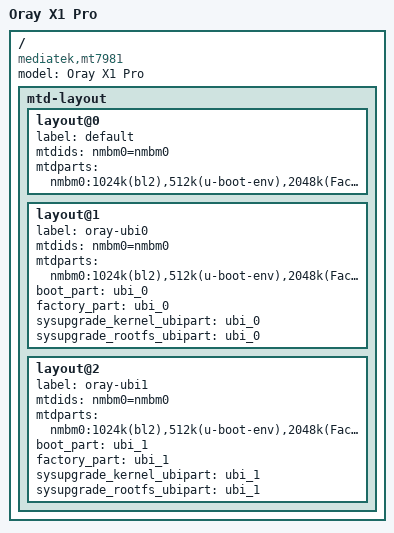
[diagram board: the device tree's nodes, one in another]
// SPDX-License-Identifier: GPL-2.0-or-later OR MIT

#include "mt7981-cudy-tr3000-v1.dts"

/ {
    compatible = "mediatek,mt7981", "mediatek,mt7981-rfb";
    model = "Oray X1 Pro";

	mtd-layout {
		layout@0 {
			label = "default";
			// mtd layout for immortalwrt/openwrt 112M ubi firmware
			mtdids = "nmbm0=nmbm0";
			mtdparts = "nmbm0:1024k(bl2),512k(u-boot-env),2048k(Factory),2048k(fip),512k(bdinfo),2048k(kpanic),114688k(ubi)";
		};

		layout@1 {
			label = "oray-ubi0";
			mtdids = "nmbm0=nmbm0";
			mtdparts = "nmbm0:1024k(bl2),512k(u-boot-env),2048k(Factory),2048k(fip),512k(bdinfo),2048k(kpanic),57344k(ubi_0),57344k(ubi_1)";
			boot_part = "ubi_0";
			factory_part = "ubi_0";
			sysupgrade_kernel_ubipart = "ubi_0";
			sysupgrade_rootfs_ubipart = "ubi_0";
		};

		layout@2 {
			label = "oray-ubi1";
			mtdids = "nmbm0=nmbm0";
			mtdparts = "nmbm0:1024k(bl2),512k(u-boot-env),2048k(Factory),2048k(fip),512k(bdinfo),2048k(kpanic),57344k(ubi_0),57344k(ubi_1)";
			boot_part = "ubi_1";
			factory_part = "ubi_1";
			sysupgrade_kernel_ubipart = "ubi_1";
			sysupgrade_rootfs_ubipart = "ubi_1";
		};
    };
};
